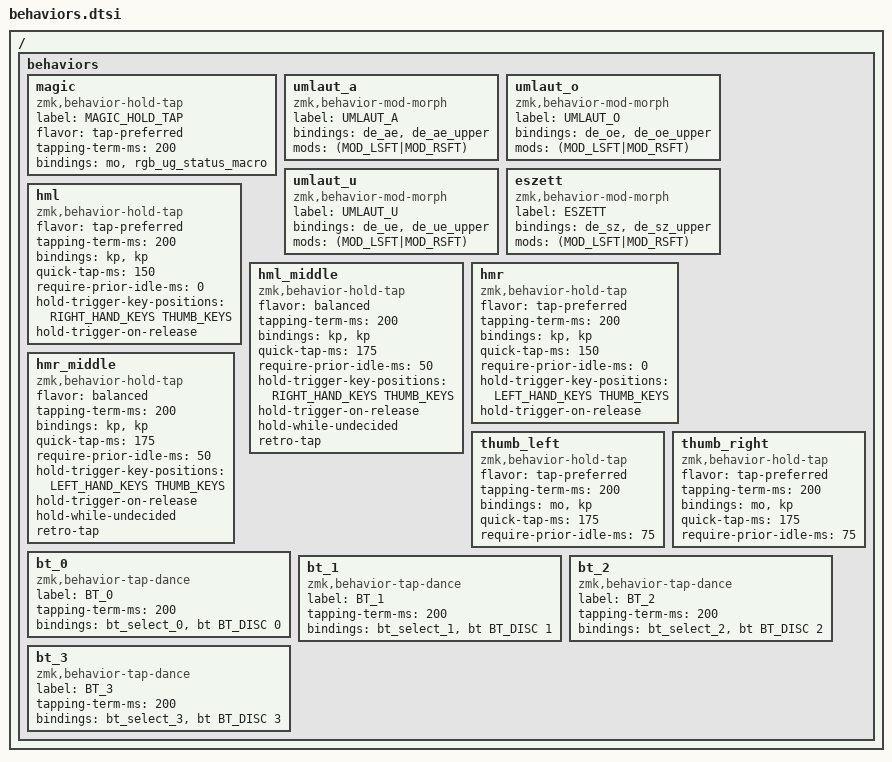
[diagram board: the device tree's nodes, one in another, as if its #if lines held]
// Extracted behaviors from Glove80 export

/ {
  behaviors {
    ZMK_TD_LAYER(lower, LAYER_Lower)

    // Magic layer behavior
    magic: magic {
      compatible = "zmk,behavior-hold-tap";
      label = "MAGIC_HOLD_TAP";
      #binding-cells = <2>;
      flavor = "tap-preferred";
      tapping-term-ms = <200>;
      bindings = <&mo>, <&rgb_ug_status_macro>;
    };

    // Umlauts
    umlaut_a: umlaut_a {
      compatible = "zmk,behavior-mod-morph";
      label = "UMLAUT_A";
      #binding-cells = <0>;
      bindings = <&de_ae>, <&de_ae_upper>;
      mods = <(MOD_LSFT|MOD_RSFT)>;
    };

    umlaut_o: umlaut_o {
      compatible = "zmk,behavior-mod-morph";
      label = "UMLAUT_O";
      #binding-cells = <0>;
      bindings = <&de_oe>, <&de_oe_upper>;
      mods = <(MOD_LSFT|MOD_RSFT)>;
    };

    umlaut_u: umlaut_u {
      compatible = "zmk,behavior-mod-morph";
      label = "UMLAUT_U";
      #binding-cells = <0>;
      bindings = <&de_ue>, <&de_ue_upper>;
      mods = <(MOD_LSFT|MOD_RSFT)>;
    };

    eszett: eszett {
      compatible = "zmk,behavior-mod-morph";
      label = "ESZETT";
      #binding-cells = <0>;
      bindings = <&de_sz>, <&de_sz_upper>;
      mods = <(MOD_LSFT|MOD_RSFT)>;
    };

    // Home row mods - left hand
    hml: hml {
      compatible = "zmk,behavior-hold-tap";
      flavor = "tap-preferred";
      #binding-cells = <2>;
      tapping-term-ms = <200>;
      bindings = <&kp>, <&kp>;
      quick-tap-ms = <150>;
      require-prior-idle-ms = <0>;
      hold-trigger-key-positions = <RIGHT_HAND_KEYS THUMB_KEYS>;
      hold-trigger-on-release;
    };
    hml_middle: hml_middle {
      compatible = "zmk,behavior-hold-tap";
      flavor = "balanced";
      #binding-cells = <2>;
      tapping-term-ms = <200>;
      bindings = <&kp>, <&kp>;
      quick-tap-ms = <175>;
      require-prior-idle-ms = <50>;
      hold-trigger-key-positions = <RIGHT_HAND_KEYS THUMB_KEYS>;
      hold-trigger-on-release;
      hold-while-undecided;
      retro-tap;
    };

    // Home row mods - right hand
    hmr: hmr {
      compatible = "zmk,behavior-hold-tap";
      flavor = "tap-preferred";
      #binding-cells = <2>;
      tapping-term-ms = <200>;
      bindings = <&kp>, <&kp>;
      quick-tap-ms = <150>;
      require-prior-idle-ms = <0>;
      hold-trigger-key-positions = <LEFT_HAND_KEYS THUMB_KEYS>;
      hold-trigger-on-release;
    };
    hmr_middle: hmr_middle {
      compatible = "zmk,behavior-hold-tap";
      flavor = "balanced";
      #binding-cells = <2>;
      tapping-term-ms = <200>;
      bindings = <&kp>, <&kp>;
      quick-tap-ms = <175>;
      require-prior-idle-ms = <50>;
      hold-trigger-key-positions = <LEFT_HAND_KEYS THUMB_KEYS>;
      hold-trigger-on-release;
      hold-while-undecided;
      retro-tap;    
    };

    // Thumb layer keys - left
    thumb_left: thumb_left {
      compatible = "zmk,behavior-hold-tap";
      flavor = "tap-preferred";
      #binding-cells = <2>;
      tapping-term-ms = <200>;
      bindings = <&mo>, <&kp>;
      quick-tap-ms = <175>;
      require-prior-idle-ms = <75>;
    };

    // Thumb layer keys - right
    thumb_right: thumb_right {
      compatible = "zmk,behavior-hold-tap";
      flavor = "tap-preferred";
      #binding-cells = <2>;
      tapping-term-ms = <200>;
      bindings = <&mo>, <&kp>;
      quick-tap-ms = <175>;
      require-prior-idle-ms = <75>;
    };

#ifdef BT_DISC_CMD
    bt_0: bt_0 {
        compatible = "zmk,behavior-tap-dance";
        label = "BT_0";
        #binding-cells = <0>;
        tapping-term-ms = <200>;
        bindings = <&bt_select_0>, <&bt BT_DISC 0>;
    };
    bt_1: bt_1 {
        compatible = "zmk,behavior-tap-dance";
        label = "BT_1";
        #binding-cells = <0>;
        tapping-term-ms = <200>;
        bindings = <&bt_select_1>, <&bt BT_DISC 1>;
    };
    bt_2: bt_2 {
        compatible = "zmk,behavior-tap-dance";
        label = "BT_2";
        #binding-cells = <0>;
        tapping-term-ms = <200>;
        bindings = <&bt_select_2>, <&bt BT_DISC 2>;
    };
    bt_3: bt_3 {
        compatible = "zmk,behavior-tap-dance";
        label = "BT_3";
        #binding-cells = <0>;
        tapping-term-ms = <200>;
        bindings = <&bt_select_3>, <&bt BT_DISC 3>;
    };
#endif
  };
};

